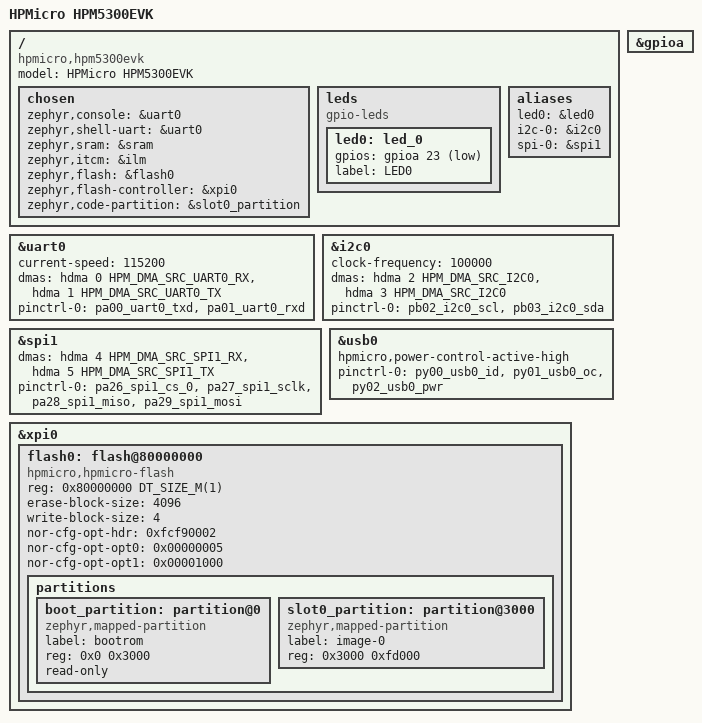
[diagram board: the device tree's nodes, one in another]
/*
 * Copyright (c) 2026 The HPM Zephyr Module Contributors
 * SPDX-License-Identifier: Apache-2.0
 */

/dts-v1/;

#include <dt-bindings/dma/hpmicro-hpm5300-dma.h>
#include <hpmicro/hpm5361.dtsi>
#include "hpm5300evk-pinctrl.dtsi"

/ {
	model = "HPMicro HPM5300EVK";
	compatible = "hpmicro,hpm5300evk";

	chosen {
		zephyr,console = &uart0;
		zephyr,shell-uart = &uart0;
		zephyr,sram = &sram;
		zephyr,itcm = &ilm;
		zephyr,flash = &flash0;
		zephyr,flash-controller = &xpi0;
		zephyr,code-partition = &slot0_partition;
	};

	leds {
		compatible = "gpio-leds";

		led0: led_0 {
			gpios = <&gpioa 23 GPIO_ACTIVE_LOW>;
			label = "LED0";
		};
	};

	aliases {
		led0 = &led0;
		i2c-0 = &i2c0;
		spi-0 = &spi1;
	};
};

&uart0 {
	status = "okay";
	current-speed = <115200>;
	dmas = <&hdma 0 HPM_DMA_SRC_UART0_RX>, <&hdma 1 HPM_DMA_SRC_UART0_TX>;
	dma-names = "rx", "tx";
	pinctrl-0 = <&pa00_uart0_txd &pa01_uart0_rxd>;
	pinctrl-names = "default";
};

&i2c0 {
	status = "okay";
	clock-frequency = <100000>;
	dmas = <&hdma 2 HPM_DMA_SRC_I2C0>, <&hdma 3 HPM_DMA_SRC_I2C0>;
	dma-names = "tx", "rx";
	pinctrl-0 = <&pb02_i2c0_scl &pb03_i2c0_sda>;
	pinctrl-names = "default";
};

&spi1 {
	status = "okay";
	dmas = <&hdma 4 HPM_DMA_SRC_SPI1_RX>, <&hdma 5 HPM_DMA_SRC_SPI1_TX>;
	dma-names = "rx", "tx";
	pinctrl-0 = <&pa26_spi1_cs_0 &pa27_spi1_sclk
		     &pa28_spi1_miso &pa29_spi1_mosi>;
	pinctrl-names = "default";
};

&usb0 {
	hpmicro,power-control-active-high;
	pinctrl-0 = <&py00_usb0_id &py01_usb0_oc &py02_usb0_pwr>;
	pinctrl-names = "default";
};

&gpioa {
	status = "okay";
};

&xpi0 {
	status = "okay";

	flash0: flash@80000000 {
		compatible = "hpmicro,hpmicro-flash", "soc-nv-flash";
		reg = <0x80000000 DT_SIZE_M(1)>;
		ranges = <0x0 0x80000000 DT_SIZE_M(1)>;
		#address-cells = <1>;
		#size-cells = <1>;
		status = "okay";
		erase-block-size = <4096>;
		write-block-size = <4>;
		nor-cfg-opt-hdr = <0xfcf90002>;
		nor-cfg-opt-opt0 = <0x00000005>;
		nor-cfg-opt-opt1 = <0x00001000>;

		partitions {
			ranges;
			#address-cells = <1>;
			#size-cells = <1>;

			boot_partition: partition@0 {
				compatible = "zephyr,mapped-partition";
				label = "bootrom";
				reg = <0x0 0x3000>;
				read-only;
			};

			slot0_partition: partition@3000 {
				compatible = "zephyr,mapped-partition";
				label = "image-0";
				reg = <0x3000 0xfd000>;
			};
		};
	};
};
